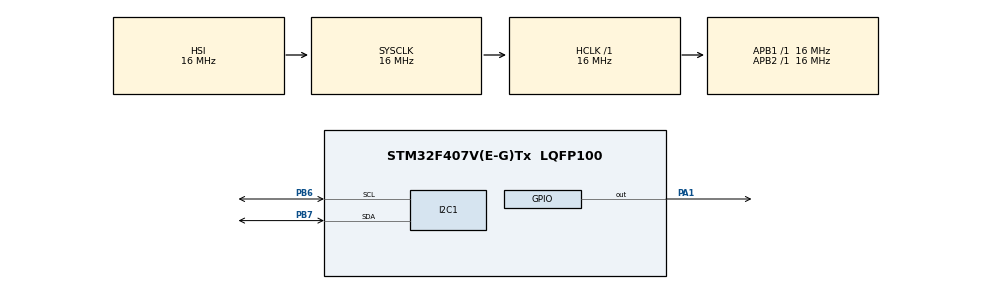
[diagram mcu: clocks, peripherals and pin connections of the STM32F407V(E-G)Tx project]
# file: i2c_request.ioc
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Mcu.Family=STM32F4
Mcu.Name=STM32F407V(E-G)Tx
Mcu.Package=LQFP100
NVIC.PriorityGroup=NVIC_PRIORITYGROUP_4
PA1.Signal=GPIO_Output
PB6.Mode=I2C
PB6.Signal=I2C1_SCL
PB7.Mode=I2C
PB7.Signal=I2C1_SDA
ProjectManager.HeapSize=0x200
ProjectManager.StackSize=0x400
ProjectManager.TargetToolchain=MDK-ARM V5.27
RCC.AHBFreq_Value=16000000
RCC.APB1Freq_Value=16000000
RCC.APB2Freq_Value=16000000
RCC.CortexFreq_Value=16000000
RCC.HSE_VALUE=25000000
RCC.HSI_VALUE=16000000
RCC.LSE_VALUE=32768
RCC.SYSCLKFreq_VALUE=16000000
RCC.VCOOutputFreq_Value=192000000
board=custom

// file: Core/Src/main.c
/* USER CODE BEGIN Header */
/**
  ******************************************************************************
  * @file           : main.c
  * @brief          : Main program body
  ******************************************************************************
  * @attention
  *
  * <h2><center>&copy; Copyright (c) 2021 STMicroelectronics.
  * All rights reserved.</center></h2>
  *
  * This software component is licensed by ST under BSD 3-Clause license,
  * the "License"; You may not use this file except in compliance with the
  * License. You may obtain a copy of the License at:
  *                        opensource.org/licenses/BSD-3-Clause
  *
  ******************************************************************************
  */
/* USER CODE END Header */
#include "main.h"
#include "i2c.h"
#include "gpio.h"

/* USER CODE BEGIN PD */
#define mpu9250Address 0xD0
/* USER CODE END PD */

/* USER CODE BEGIN PV */
uint8_t i=0;
uint8_t i2cBuf[8];
int16_t ax,ay,az;
float Xaccel,Yaccel,Zaccel;
/* USER CODE END PV */

void SystemClock_Config(void);
/* USER CODE BEGIN PFP */
uint8_t i2cBuf[8];
/* USER CODE END PFP */

int main(void)
{

  /* MCU Configuration--------------------------------------------------------*/

  /* Reset of all peripherals, Initializes the Flash interface and the Systick. */
  HAL_Init();

  /* Configure the system clock */
  SystemClock_Config();

  /* Initialize all configured peripherals */
  MX_GPIO_Init();
  MX_I2C1_Init();
  /* USER CODE BEGIN 2 */
	//Scan the I2C address
	/*for( i=0 ; i <255 ; i++){
		if(HAL_I2C_IsDeviceReady(&hi2c1,i,1,10)==HAL_OK){
			HAL_GPIO_TogglePin(GPIOA,GPIO_PIN_1);
			break;
		}
	}*/

	//2. I2C Write example
	//a) Set accelerometer range (reg28)
	i2cBuf[0] = 28;			//Register address: Accelerometer config 1
	i2cBuf[1] = 0x08;		//Data to write, +-4g range
	HAL_I2C_Master_Transmit(&hi2c1, mpu9250Address, i2cBuf, 2, 10);
	//3. I2C Read example
	//Request to read from a register (reg28)
	i2cBuf[0] = 28;			//Register address: Accelerometer config 1
	HAL_I2C_Master_Transmit(&hi2c1 , mpu9250Address, i2cBuf, 1, 10);
	//Read data
	i2cBuf[1] = 0x00;
	HAL_I2C_Master_Receive(&hi2c1, mpu9250Address|0x01, &i2cBuf[1], 1, 10);
  /* USER CODE END 2 */

  /* Infinite loop */
  while (1)
  {

    /* USER CODE BEGIN 3 */

		//4. Read accelerometer data
		//Request to read from a register
		i2cBuf[0] = 0x3B;			//Register address: X_axis H
		HAL_I2C_Master_Transmit(&hi2c1, mpu9250Address, i2cBuf, 1, 10);
		//Read data
		i2cBuf[1] = 0x00;
		HAL_I2C_Master_Receive(&hi2c1, mpu9250Address|0x01, &i2cBuf[1], 6, 10);
		ax = -(i2cBuf[1]<<8 | i2cBuf[2]);
		ay = -(i2cBuf[3]<<8 | i2cBuf[4]);
		az = 	(i2cBuf[5]<<8 | i2cBuf[6]);
		Xaccel = ax/8192.0;
		Yaccel = ay/8192.0;
		Zaccel = az/8192.0;
		HAL_GPIO_TogglePin(GPIOA , GPIO_PIN_1);
		HAL_Delay(50);

  }

  /* USER CODE END 3 */
}

void SystemClock_Config(void)
{
  RCC_OscInitTypeDef RCC_OscInitStruct = {0};
  RCC_ClkInitTypeDef RCC_ClkInitStruct = {0};

  /** Configure the main internal regulator output voltage
  */
  __HAL_RCC_PWR_CLK_ENABLE();
  __HAL_PWR_VOLTAGESCALING_CONFIG(PWR_REGULATOR_VOLTAGE_SCALE1);
  /** Initializes the RCC Oscillators according to the specified parameters
  * in the RCC_OscInitTypeDef structure.
  */
  RCC_OscInitStruct.OscillatorType = RCC_OSCILLATORTYPE_HSI;
  RCC_OscInitStruct.HSIState = RCC_HSI_ON;
  RCC_OscInitStruct.HSICalibrationValue = RCC_HSICALIBRATION_DEFAULT;
  RCC_OscInitStruct.PLL.PLLState = RCC_PLL_NONE;
  if (HAL_RCC_OscConfig(&RCC_OscInitStruct) != HAL_OK)
  {
    Error_Handler();
  }
  /** Initializes the CPU, AHB and APB buses clocks
  */
  RCC_ClkInitStruct.ClockType = RCC_CLOCKTYPE_HCLK|RCC_CLOCKTYPE_SYSCLK
                              |RCC_CLOCKTYPE_PCLK1|RCC_CLOCKTYPE_PCLK2;
  RCC_ClkInitStruct.SYSCLKSource = RCC_SYSCLKSOURCE_HSI;
  RCC_ClkInitStruct.AHBCLKDivider = RCC_SYSCLK_DIV1;
  RCC_ClkInitStruct.APB1CLKDivider = RCC_HCLK_DIV1;
  RCC_ClkInitStruct.APB2CLKDivider = RCC_HCLK_DIV1;

  if (HAL_RCC_ClockConfig(&RCC_ClkInitStruct, FLASH_LATENCY_0) != HAL_OK)
  {
    Error_Handler();
  }
}

void Error_Handler(void)
{
}

/************************ (C) COPYRIGHT STMicroelectronics *****END OF FILE****/
